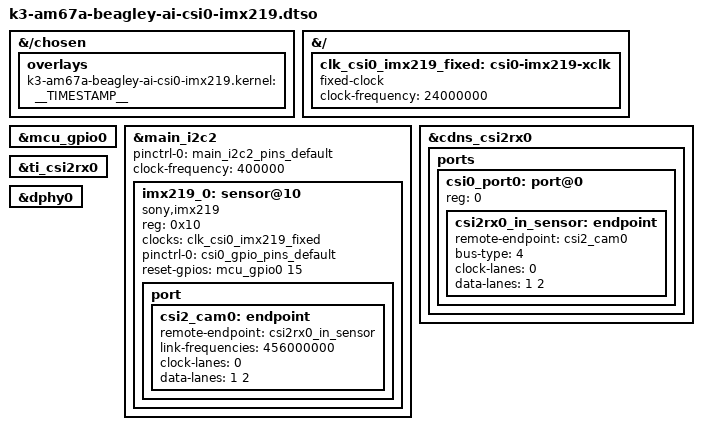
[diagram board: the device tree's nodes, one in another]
// SPDX-License-Identifier: GPL-2.0
/*
 * DT Overlay for RPi Camera V2.1 on CSI0 J722S BeagleY-AI board.
 *
 * Copyright (C) 2023 Texas Instruments Incorporated - https://www.ti.com/
 *
 * Schematics: https://datasheets.raspberrypi.com/camera/camera-v2-schematics.pdf
 */

/dts-v1/;
/plugin/;

#include <dt-bindings/gpio/gpio.h>

/*
 * Helper to show loaded overlays under: /proc/device-tree/chosen/overlays/
 */
&{/chosen} {
	overlays {
		k3-am67a-beagley-ai-csi0-imx219.kernel = __TIMESTAMP__;
	};
};

&{/} {
	clk_csi0_imx219_fixed: csi0-imx219-xclk {
		compatible = "fixed-clock";
		#clock-cells = <0>;
		clock-frequency = <24000000>;
	};
};

&mcu_gpio0 {
    status = "okay";
};

&main_i2c2 {
	status = "okay";
	pinctrl-names = "default";
	pinctrl-0 = <&main_i2c2_pins_default>;
	clock-frequency = <400000>;

	#address-cells = <1>;
	#size-cells = <0>;

	imx219_0: sensor@10 {
		compatible = "sony,imx219";
		reg = <0x10>;

		clocks = <&clk_csi0_imx219_fixed>;
		clock-names = "xclk";

		pinctrl-names = "default";
		pinctrl-0 = <&csi0_gpio_pins_default>;

		reset-gpios = <&mcu_gpio0 15 GPIO_ACTIVE_HIGH>;

		port {
			csi2_cam0: endpoint {
				remote-endpoint = <&csi2rx0_in_sensor>;
				link-frequencies = /bits/ 64 <456000000>;
				clock-lanes = <0>;
				data-lanes = <1 2>;
			};
		};
	};
};

&cdns_csi2rx0 {
	ports {
		#address-cells = <1>;
		#size-cells = <0>;

		csi0_port0: port@0 {
			reg = <0>;
			status = "okay";

			csi2rx0_in_sensor: endpoint {
				remote-endpoint = <&csi2_cam0>;
				bus-type = <4>; /* CSI2 DPHY */
				clock-lanes = <0>;
				data-lanes = <1 2>;
			};
		};
	};
};

&ti_csi2rx0 {
	status = "okay";
};

&dphy0 {
	status = "okay";
};
